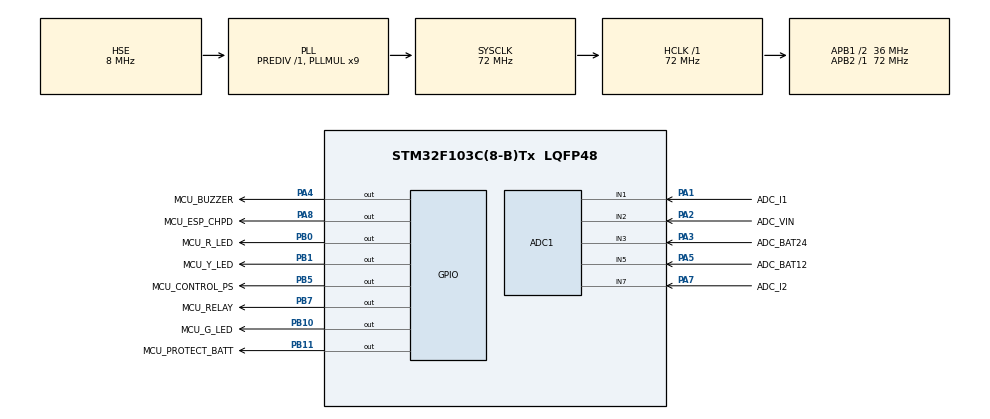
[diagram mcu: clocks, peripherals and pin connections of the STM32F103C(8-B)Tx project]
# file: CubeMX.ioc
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ADC1.Channel-0\#ChannelRegularConversion=ADC_CHANNEL_1
ADC1.Channel-1\#ChannelRegularConversion=ADC_CHANNEL_1
ADC1.Channel-2\#ChannelRegularConversion=ADC_CHANNEL_1
ADC1.Channel-3\#ChannelRegularConversion=ADC_CHANNEL_1
ADC1.Channel-4\#ChannelRegularConversion=ADC_CHANNEL_1
ADC1.ContinuousConvMode=ENABLE
ADC1.NbrOfConversion=5
ADC1.NbrOfConversionFlag=1
ADC1.Rank-0\#ChannelRegularConversion=1
ADC1.Rank-1\#ChannelRegularConversion=2
ADC1.Rank-2\#ChannelRegularConversion=3
ADC1.Rank-3\#ChannelRegularConversion=4
ADC1.Rank-4\#ChannelRegularConversion=5
ADC1.SamplingTime-0\#ChannelRegularConversion=ADC_SAMPLETIME_1CYCLE_5
ADC1.SamplingTime-1\#ChannelRegularConversion=ADC_SAMPLETIME_1CYCLE_5
ADC1.SamplingTime-2\#ChannelRegularConversion=ADC_SAMPLETIME_1CYCLE_5
ADC1.SamplingTime-3\#ChannelRegularConversion=ADC_SAMPLETIME_1CYCLE_5
ADC1.SamplingTime-4\#ChannelRegularConversion=ADC_SAMPLETIME_1CYCLE_5
ADC1.master=1
Dma.ADC1.0.Direction=DMA_PERIPH_TO_MEMORY
Dma.ADC1.0.Instance=DMA1_Channel1
Dma.ADC1.0.MemDataAlignment=DMA_MDATAALIGN_HALFWORD
Dma.ADC1.0.MemInc=DMA_MINC_ENABLE
Dma.ADC1.0.Mode=DMA_CIRCULAR
Dma.ADC1.0.PeriphDataAlignment=DMA_PDATAALIGN_HALFWORD
Dma.ADC1.0.PeriphInc=DMA_PINC_DISABLE
Dma.ADC1.0.Priority=DMA_PRIORITY_MEDIUM
Dma.Request0=ADC1
FREERTOS.Tasks01=defaultTask,24,128,StartDefaultTask,Default,NULL,Dynamic,NULL,NULL
Mcu.Family=STM32F1
Mcu.Name=STM32F103C(8-B)Tx
Mcu.Package=LQFP48
NVIC.DMA1_Channel1_IRQn=true\:5\:0\:false\:false\:true\:true\:false\:true\:true
NVIC.PriorityGroup=NVIC_PRIORITYGROUP_4
PA1.GPIO_Label=ADC_I1
PA1.Signal=ADCx_IN1
PA13.Mode=Serial_Wire
PA13.Signal=SYS_JTMS-SWDIO
PA14.Mode=Serial_Wire
PA14.Signal=SYS_JTCK-SWCLK
PA2.GPIO_Label=ADC_VIN
PA2.Signal=ADCx_IN2
PA3.GPIO_Label=ADC_BAT24
PA3.Signal=ADCx_IN3
PA4.GPIO_Label=MCU_BUZZER
PA4.Signal=GPIO_Output
PA5.GPIO_Label=ADC_BAT12
PA5.Signal=ADCx_IN5
PA7.GPIO_Label=ADC_I2
PA7.Signal=ADCx_IN7
PA8.GPIO_Label=MCU_ESP_CHPD
PA8.Signal=GPIO_Output
PB0.GPIO_Label=MCU_R_LED
PB0.Signal=GPIO_Output
PB1.GPIO_Label=MCU_Y_LED
PB1.Signal=GPIO_Output
PB10.GPIO_Label=MCU_G_LED
PB10.Signal=GPIO_Output
PB11.GPIO_Label=MCU_PROTECT_BATT
PB11.Signal=GPIO_Output
PB5.GPIO_Label=MCU_CONTROL_PS
PB5.Signal=GPIO_Output
PB7.GPIO_Label=MCU_RELAY
PB7.Signal=GPIO_Output
PD0-OSC_IN.Mode=HSE-External-Oscillator
PD0-OSC_IN.Signal=RCC_OSC_IN
PD1-OSC_OUT.Mode=HSE-External-Oscillator
PD1-OSC_OUT.Signal=RCC_OSC_OUT
ProjectManager.HeapSize=0x200
ProjectManager.StackSize=0x400
ProjectManager.TargetToolchain=STM32CubeIDE
RCC.AHBFreq_Value=72000000
RCC.APB1CLKDivider=RCC_HCLK_DIV2
RCC.APB1Freq_Value=36000000
RCC.APB1TimFreq_Value=72000000
RCC.APB2Freq_Value=72000000
RCC.APB2TimFreq_Value=72000000
RCC.EnbaleCSS=true
RCC.HCLKFreq_Value=72000000
RCC.PLLMUL=RCC_PLL_MUL9
RCC.PLLSourceVirtual=RCC_PLLSOURCE_HSE
RCC.SYSCLKFreq_VALUE=72000000
RCC.SYSCLKSource=RCC_SYSCLKSOURCE_PLLCLK
RCC.USBFreq_Value=72000000
SH.ADCx_IN1.0=ADC1_IN1,IN1
SH.ADCx_IN2.0=ADC1_IN2,IN2
SH.ADCx_IN3.0=ADC1_IN3,IN3
SH.ADCx_IN5.0=ADC1_IN5,IN5
SH.ADCx_IN7.0=ADC1_IN7,IN7
VP_FREERTOS_VS_CMSIS_V2.Mode=CMSIS_V2
board=custom

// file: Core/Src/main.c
/* USER CODE BEGIN Header */
/**
  ******************************************************************************
  * @file           : main.c
  * @brief          : Main program body
  ******************************************************************************
  * @attention
  *
  * Copyright (c) 2026 STMicroelectronics.
  * All rights reserved.
  *
  * This software is licensed under terms that can be found in the LICENSE file
  * in the root directory of this software component.
  * If no LICENSE file comes with this software, it is provided AS-IS.
  *
  ******************************************************************************
  */
/* USER CODE END Header */
#include "main.h"
#include "cmsis_os.h"

/* USER CODE BEGIN Includes */
#include "app.h"
/* USER CODE END Includes */

ADC_HandleTypeDef hadc1;
DMA_HandleTypeDef hdma_adc1;

/* Definitions for defaultTask */
osThreadId_t defaultTaskHandle;
const osThreadAttr_t defaultTask_attributes = {
  .name = "defaultTask",
  .stack_size = 128 * 4,
  .priority = (osPriority_t) osPriorityNormal,
};

void SystemClock_Config(void);
static void MX_GPIO_Init(void);
static void MX_DMA_Init(void);
static void MX_ADC1_Init(void);
void StartDefaultTask(void *argument);

int main(void)
{

  /* MCU Configuration--------------------------------------------------------*/

  /* Reset of all peripherals, Initializes the Flash interface and the Systick. */
  HAL_Init();

  /* Configure the system clock */
  SystemClock_Config();

  /* Initialize all configured peripherals */
  MX_GPIO_Init();
  MX_DMA_Init();
  MX_ADC1_Init();
  /* USER CODE BEGIN 2 */
  /* App_Start does not return. CubeMX osKernelStart below is never reached. */
  App_Start();
  /* USER CODE END 2 */

  /* Init scheduler */
  osKernelInitialize();

  /* Create the thread(s) */
  /* creation of defaultTask */
  defaultTaskHandle = osThreadNew(StartDefaultTask, NULL, &defaultTask_attributes);

  /* Start scheduler */
  osKernelStart();

  /* We should never get here as control is now taken by the scheduler */

  /* Infinite loop */
  while (1)
  {

  }
}

void SystemClock_Config(void)
{
  RCC_OscInitTypeDef RCC_OscInitStruct = {0};
  RCC_ClkInitTypeDef RCC_ClkInitStruct = {0};
  RCC_PeriphCLKInitTypeDef PeriphClkInit = {0};

  /** Initializes the RCC Oscillators according to the specified parameters
  * in the RCC_OscInitTypeDef structure.
  */
  RCC_OscInitStruct.OscillatorType = RCC_OSCILLATORTYPE_HSE;
  RCC_OscInitStruct.HSEState = RCC_HSE_ON;
  RCC_OscInitStruct.HSEPredivValue = RCC_HSE_PREDIV_DIV1;
  RCC_OscInitStruct.HSIState = RCC_HSI_ON;
  RCC_OscInitStruct.PLL.PLLState = RCC_PLL_ON;
  RCC_OscInitStruct.PLL.PLLSource = RCC_PLLSOURCE_HSE;
  RCC_OscInitStruct.PLL.PLLMUL = RCC_PLL_MUL9;
  if (HAL_RCC_OscConfig(&RCC_OscInitStruct) != HAL_OK)
  {
    Error_Handler();
  }

  /** Initializes the CPU, AHB and APB buses clocks
  */
  RCC_ClkInitStruct.ClockType = RCC_CLOCKTYPE_HCLK|RCC_CLOCKTYPE_SYSCLK
                              |RCC_CLOCKTYPE_PCLK1|RCC_CLOCKTYPE_PCLK2;
  RCC_ClkInitStruct.SYSCLKSource = RCC_SYSCLKSOURCE_PLLCLK;
  RCC_ClkInitStruct.AHBCLKDivider = RCC_SYSCLK_DIV1;
  RCC_ClkInitStruct.APB1CLKDivider = RCC_HCLK_DIV2;
  RCC_ClkInitStruct.APB2CLKDivider = RCC_HCLK_DIV1;

  if (HAL_RCC_ClockConfig(&RCC_ClkInitStruct, FLASH_LATENCY_2) != HAL_OK)
  {
    Error_Handler();
  }
  PeriphClkInit.PeriphClockSelection = RCC_PERIPHCLK_ADC;
  PeriphClkInit.AdcClockSelection = RCC_ADCPCLK2_DIV6;
  if (HAL_RCCEx_PeriphCLKConfig(&PeriphClkInit) != HAL_OK)
  {
    Error_Handler();
  }

  /** Enables the Clock Security System
  */
  HAL_RCC_EnableCSS();
}

static void MX_ADC1_Init(void)
{

  ADC_ChannelConfTypeDef sConfig = {0};

  /** Common config
  */
  hadc1.Instance = ADC1;
  hadc1.Init.ScanConvMode = ADC_SCAN_ENABLE;
  hadc1.Init.ContinuousConvMode = ENABLE;
  hadc1.Init.DiscontinuousConvMode = DISABLE;
  hadc1.Init.ExternalTrigConv = ADC_SOFTWARE_START;
  hadc1.Init.DataAlign = ADC_DATAALIGN_RIGHT;
  hadc1.Init.NbrOfConversion = 5;
  if (HAL_ADC_Init(&hadc1) != HAL_OK)
  {
    Error_Handler();
  }

  /** Configure Regular Channel
  */
  sConfig.Channel = ADC_CHANNEL_1;
  sConfig.Rank = ADC_REGULAR_RANK_1;
  sConfig.SamplingTime = ADC_SAMPLETIME_1CYCLE_5;
  if (HAL_ADC_ConfigChannel(&hadc1, &sConfig) != HAL_OK)
  {
    Error_Handler();
  }

  /** Configure Regular Channel
  */
  sConfig.Rank = ADC_REGULAR_RANK_2;
  if (HAL_ADC_ConfigChannel(&hadc1, &sConfig) != HAL_OK)
  {
    Error_Handler();
  }

  /** Configure Regular Channel
  */
  sConfig.Rank = ADC_REGULAR_RANK_3;
  if (HAL_ADC_ConfigChannel(&hadc1, &sConfig) != HAL_OK)
  {
    Error_Handler();
  }

  /** Configure Regular Channel
  */
  sConfig.Rank = ADC_REGULAR_RANK_4;
  if (HAL_ADC_ConfigChannel(&hadc1, &sConfig) != HAL_OK)
  {
    Error_Handler();
  }

  /** Configure Regular Channel
  */
  sConfig.Rank = ADC_REGULAR_RANK_5;
  if (HAL_ADC_ConfigChannel(&hadc1, &sConfig) != HAL_OK)
  {
    Error_Handler();
  }

}

static void MX_DMA_Init(void)
{

  /* DMA controller clock enable */
  __HAL_RCC_DMA1_CLK_ENABLE();

  /* DMA interrupt init */
  /* DMA1_Channel1_IRQn interrupt configuration */
  HAL_NVIC_SetPriority(DMA1_Channel1_IRQn, 5, 0);
  HAL_NVIC_EnableIRQ(DMA1_Channel1_IRQn);

}

static void MX_GPIO_Init(void)
{
  GPIO_InitTypeDef GPIO_InitStruct = {0};

  /* GPIO Ports Clock Enable */
  __HAL_RCC_GPIOD_CLK_ENABLE();
  __HAL_RCC_GPIOA_CLK_ENABLE();
  __HAL_RCC_GPIOB_CLK_ENABLE();

  /*Configure GPIO pin Output Level */
  HAL_GPIO_WritePin(GPIOA, MCU_BUZZER_Pin|MCU_ESP_CHPD_Pin, GPIO_PIN_RESET);

  /*Configure GPIO pin Output Level */
  HAL_GPIO_WritePin(GPIOB, MCU_R_LED_Pin|MCU_Y_LED_Pin|MCU_G_LED_Pin|MCU_PROTECT_BATT_Pin
                          |MCU_CONTROL_PS_Pin|MCU_RELAY_Pin, GPIO_PIN_RESET);

  /*Configure GPIO pins : MCU_BUZZER_Pin MCU_ESP_CHPD_Pin */
  GPIO_InitStruct.Pin = MCU_BUZZER_Pin|MCU_ESP_CHPD_Pin;
  GPIO_InitStruct.Mode = GPIO_MODE_OUTPUT_PP;
  GPIO_InitStruct.Pull = GPIO_NOPULL;
  GPIO_InitStruct.Speed = GPIO_SPEED_FREQ_LOW;
  HAL_GPIO_Init(GPIOA, &GPIO_InitStruct);

  /*Configure GPIO pins : MCU_R_LED_Pin MCU_Y_LED_Pin MCU_G_LED_Pin MCU_PROTECT_BATT_Pin
                           MCU_CONTROL_PS_Pin MCU_RELAY_Pin */
  GPIO_InitStruct.Pin = MCU_R_LED_Pin|MCU_Y_LED_Pin|MCU_G_LED_Pin|MCU_PROTECT_BATT_Pin
                          |MCU_CONTROL_PS_Pin|MCU_RELAY_Pin;
  GPIO_InitStruct.Mode = GPIO_MODE_OUTPUT_PP;
  GPIO_InitStruct.Pull = GPIO_NOPULL;
  GPIO_InitStruct.Speed = GPIO_SPEED_FREQ_LOW;
  HAL_GPIO_Init(GPIOB, &GPIO_InitStruct);

}

void StartDefaultTask(void *argument)
{
  for(;;)
  {
    osDelay(1);
  }
}

void Error_Handler(void)
{
  __disable_irq();
  while (1)
  {
  }
}
